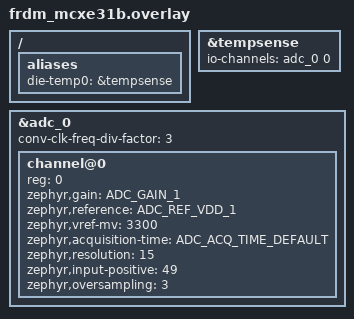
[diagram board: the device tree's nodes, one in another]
/*
 * Copyright 2025 NXP
 *
 * SPDX-License-Identifier: Apache-2.0
 */

#include <zephyr/dt-bindings/adc/adc.h>

/ {
	aliases {
		die-temp0 = &tempsense;
	};
};

&tempsense {
	status = "okay";
	io-channels = <&adc_0 0>;
};

&adc_0 {
	status = "okay";
	#address-cells = <1>;
	#size-cells = <0>;

	conv-clk-freq-div-factor = <3>;

	channel@0 {
		reg = <0>;
		zephyr,gain = "ADC_GAIN_1";
		zephyr,reference = "ADC_REF_VDD_1";
		zephyr,vref-mv = <3300>;
		zephyr,acquisition-time = <ADC_ACQ_TIME_DEFAULT>;
		zephyr,resolution = <15>;
		zephyr,input-positive = <49>;
		zephyr,oversampling = <3>;
	};
};
